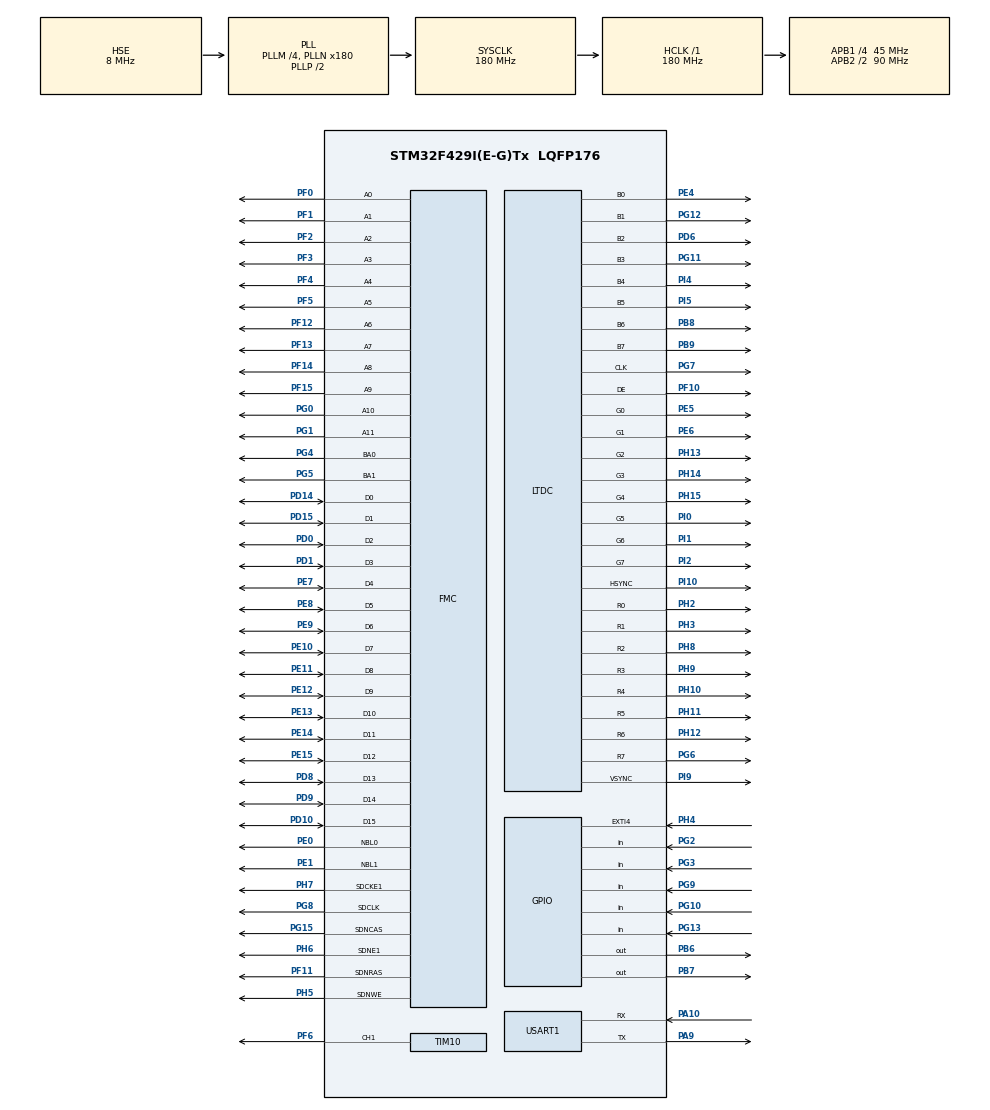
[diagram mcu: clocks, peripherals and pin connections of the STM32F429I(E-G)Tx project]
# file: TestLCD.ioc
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DMA2D.BytesSwap=DMA2D_BYTES_REGULAR
DMA2D.ColorMode=DMA2D_OUTPUT_RGB565
DMA2D.Mode=DMA2D_M2M
FMC.CASLatency1=FMC_SDRAM_CAS_LATENCY_3
FMC.ExitSelfRefreshDelay1=7
FMC.LoadToActiveDelay1=2
FMC.RCDDelay1=2
FMC.RPDelay1=2
FMC.RPDelay2=2
FMC.ReadBurst1=FMC_SDRAM_RBURST_ENABLE
FMC.ReadBurst2=FMC_SDRAM_RBURST_ENABLE
FMC.ReadPipeDelay1=FMC_SDRAM_RPIPE_DELAY_1
FMC.ReadPipeDelay2=FMC_SDRAM_RPIPE_DELAY_1
FMC.RowCycleDelay1=6
FMC.RowCycleDelay2=6
FMC.SDClockPeriod1=FMC_SDRAM_CLOCK_PERIOD_2
FMC.SDClockPeriod2=FMC_SDRAM_CLOCK_PERIOD_2
FMC.SelfRefreshTime1=4
FMC.WriteRecoveryTime1=2
FREERTOS.Tasks01=defaultTask,0,4096,StartDefaultTask,Default,NULL,Dynamic,NULL,NULL
FREERTOS.configTOTAL_HEAP_SIZE=30000
LTDC.ActiveW=800
LTDC.Alpha_L0=255
LTDC.FBStartAdress_L0=0xD0000000
LTDC.HBP=13
LTDC.HFP=32
LTDC.HSync=41
LTDC.ImageHeight_L0=480
LTDC.ImageWidth_L0=800
LTDC.Layers=0
LTDC.PixelFormat_L0=LTDC_PIXEL_FORMAT_RGB565
LTDC.VSync=10
LTDC.WindowX1_L0=800
LTDC.WindowY1_L0=480
Mcu.Family=STM32F4
Mcu.Name=STM32F429I(E-G)Tx
Mcu.Package=LQFP176
NVIC.DMA2D_IRQn=true\:5\:0\:false\:false\:true\:true\:true\:true
NVIC.EXTI4_IRQn=true\:0\:0\:false\:false\:true\:false\:true\:true
NVIC.LTDC_IRQn=true\:5\:0\:false\:false\:true\:true\:true\:true
NVIC.PriorityGroup=NVIC_PRIORITYGROUP_4
NVIC.TIM6_DAC_IRQn=true\:0\:0\:false\:false\:true\:false\:false\:true
NVIC.TimeBase=TIM6_DAC_IRQn
NVIC.TimeBaseIP=TIM6
PA10.Mode=Asynchronous
PA10.Signal=USART1_RX
PA13.Mode=Serial_Wire
PA13.Signal=SYS_JTMS-SWDIO
PA14.Mode=Serial_Wire
PA14.Signal=SYS_JTCK-SWCLK
PA9.Mode=Asynchronous
PA9.Signal=USART1_TX
PB6.GPIO_Speed=GPIO_SPEED_FREQ_VERY_HIGH
PB6.Signal=GPIO_Output
PB7.GPIO_Speed=GPIO_SPEED_FREQ_VERY_HIGH
PB7.Signal=GPIO_Output
PB8.GPIO_Speed=GPIO_SPEED_FREQ_VERY_HIGH
PB8.Mode=RGB888
PB8.Signal=LTDC_B6
PB9.GPIO_Speed=GPIO_SPEED_FREQ_VERY_HIGH
PB9.Mode=RGB888
PB9.Signal=LTDC_B7
PD0.Signal=FMC_D2_DA2
PD1.Signal=FMC_D3_DA3
PD10.Signal=FMC_D15_DA15
PD14.Signal=FMC_D0_DA0
PD15.Signal=FMC_D1_DA1
PD6.GPIO_Speed=GPIO_SPEED_FREQ_VERY_HIGH
PD6.Mode=RGB888
PD6.Signal=LTDC_B2
PD8.Signal=FMC_D13_DA13
PD9.Signal=FMC_D14_DA14
PE0.Signal=FMC_NBL0
PE1.Signal=FMC_NBL1
PE10.Signal=FMC_D7_DA7
PE11.Signal=FMC_D8_DA8
PE12.Signal=FMC_D9_DA9
PE13.Signal=FMC_D10_DA10
PE14.Signal=FMC_D11_DA11
PE15.Signal=FMC_D12_DA12
PE4.GPIO_Speed=GPIO_SPEED_FREQ_VERY_HIGH
PE4.Mode=RGB888
PE4.Signal=LTDC_B0
PE5.GPIO_Speed=GPIO_SPEED_FREQ_VERY_HIGH
PE5.Mode=RGB888
PE5.Signal=LTDC_G0
PE6.GPIO_Speed=GPIO_SPEED_FREQ_VERY_HIGH
PE6.Mode=RGB888
PE6.Signal=LTDC_G1
PE7.Signal=FMC_D4_DA4
PE8.Signal=FMC_D5_DA5
PE9.Signal=FMC_D6_DA6
PF0.Signal=FMC_A0
PF1.Signal=FMC_A1
PF10.GPIO_Speed=GPIO_SPEED_FREQ_VERY_HIGH
PF10.Mode=RGB888
PF10.Signal=LTDC_DE
PF11.Signal=FMC_SDNRAS
PF12.Signal=FMC_A6
PF13.Signal=FMC_A7
PF14.Signal=FMC_A8
PF15.Signal=FMC_A9
PF2.Signal=FMC_A2
PF3.Signal=FMC_A3
PF4.Signal=FMC_A4
PF5.Signal=FMC_A5
PF6.Signal=S_TIM10_CH1
PG0.Signal=FMC_A10
PG1.Signal=FMC_A11
PG10.Signal=GPIO_Input
PG11.GPIO_Speed=GPIO_SPEED_FREQ_VERY_HIGH
PG11.Mode=RGB888
PG11.Signal=LTDC_B3
PG12.GPIO_Speed=GPIO_SPEED_FREQ_VERY_HIGH
PG12.Mode=RGB888
PG12.Signal=LTDC_B1
PG13.Signal=GPIO_Input
PG15.Signal=FMC_SDNCAS
PG2.Signal=GPIO_Input
PG3.Signal=GPIO_Input
PG4.Signal=FMC_A14_BA0
PG5.Signal=FMC_A15_BA1
PG6.GPIO_Speed=GPIO_SPEED_FREQ_VERY_HIGH
PG6.Mode=RGB888
PG6.Signal=LTDC_R7
PG7.GPIO_Speed=GPIO_SPEED_FREQ_VERY_HIGH
PG7.Mode=RGB888
PG7.Signal=LTDC_CLK
PG8.Signal=FMC_SDCLK
PG9.Signal=GPIO_Input
PH0/OSC_IN.Mode=HSE-External-Oscillator
PH0/OSC_IN.Signal=RCC_OSC_IN
PH1/OSC_OUT.Mode=HSE-External-Oscillator
PH1/OSC_OUT.Signal=RCC_OSC_OUT
PH10.GPIO_Speed=GPIO_SPEED_FREQ_VERY_HIGH
PH10.Mode=RGB888
PH10.Signal=LTDC_R4
PH11.GPIO_Speed=GPIO_SPEED_FREQ_VERY_HIGH
PH11.Mode=RGB888
PH11.Signal=LTDC_R5
PH12.GPIO_Speed=GPIO_SPEED_FREQ_VERY_HIGH
PH12.Mode=RGB888
PH12.Signal=LTDC_R6
PH13.GPIO_Speed=GPIO_SPEED_FREQ_VERY_HIGH
PH13.Mode=RGB888
PH13.Signal=LTDC_G2
PH14.GPIO_Speed=GPIO_SPEED_FREQ_VERY_HIGH
PH14.Mode=RGB888
PH14.Signal=LTDC_G3
PH15.GPIO_Speed=GPIO_SPEED_FREQ_VERY_HIGH
PH15.Mode=RGB888
PH15.Signal=LTDC_G4
PH2.GPIO_Speed=GPIO_SPEED_FREQ_VERY_HIGH
PH2.Mode=RGB888
PH2.Signal=LTDC_R0
PH3.GPIO_Speed=GPIO_SPEED_FREQ_VERY_HIGH
PH3.Mode=RGB888
PH3.Signal=LTDC_R1
PH4.Signal=GPXTI4
PH5.Signal=FMC_SDNWE
PH6.Mode=SdramChipSelect2_1
PH6.Signal=FMC_SDNE1
PH7.Mode=SdramChipSelect2_1
PH7.Signal=FMC_SDCKE1
PH8.GPIO_Speed=GPIO_SPEED_FREQ_VERY_HIGH
PH8.Mode=RGB888
PH8.Signal=LTDC_R2
PH9.GPIO_Speed=GPIO_SPEED_FREQ_VERY_HIGH
PH9.Mode=RGB888
PH9.Signal=LTDC_R3
PI0.GPIO_Speed=GPIO_SPEED_FREQ_VERY_HIGH
PI0.Mode=RGB888
PI0.Signal=LTDC_G5
PI1.GPIO_Speed=GPIO_SPEED_FREQ_VERY_HIGH
PI1.Mode=RGB888
PI1.Signal=LTDC_G6
PI10.GPIO_Speed=GPIO_SPEED_FREQ_VERY_HIGH
PI10.Mode=RGB888
PI10.Signal=LTDC_HSYNC
PI2.GPIO_Speed=GPIO_SPEED_FREQ_VERY_HIGH
PI2.Mode=RGB888
PI2.Signal=LTDC_G7
PI4.GPIO_Speed=GPIO_SPEED_FREQ_VERY_HIGH
PI4.Mode=RGB888
PI4.Signal=LTDC_B4
PI5.GPIO_Speed=GPIO_SPEED_FREQ_VERY_HIGH
PI5.Mode=RGB888
PI5.Signal=LTDC_B5
PI9.GPIO_Speed=GPIO_SPEED_FREQ_VERY_HIGH
PI9.Mode=RGB888
PI9.Signal=LTDC_VSYNC
ProjectManager.HeapSize=0x200
ProjectManager.StackSize=0x400
ProjectManager.TargetToolchain=TrueSTUDIO
RCC.48MHZClocksFreq_Value=90000000
RCC.AHBFreq_Value=180000000
RCC.APB1CLKDivider=RCC_HCLK_DIV4
RCC.APB1Freq_Value=45000000
RCC.APB1TimFreq_Value=90000000
RCC.APB2CLKDivider=RCC_HCLK_DIV2
RCC.APB2Freq_Value=90000000
RCC.APB2TimFreq_Value=180000000
RCC.CortexFreq_Value=180000000
RCC.HCLKFreq_Value=180000000
RCC.HSE_VALUE=8000000
RCC.HSI_VALUE=16000000
RCC.LSE_VALUE=32768
RCC.PLLM=4
RCC.PLLN=180
RCC.PLLSAIN=50
RCC.PLLSourceVirtual=RCC_PLLSOURCE_HSE
RCC.SYSCLKFreq_VALUE=180000000
RCC.SYSCLKSource=RCC_SYSCLKSOURCE_PLLCLK
RCC.VCOOutputFreq_Value=360000000
SH.FMC_A0.0=FMC_A0,12b-sda1
SH.FMC_A1.0=FMC_A1,12b-sda1
SH.FMC_A10.0=FMC_A10,12b-sda1
SH.FMC_A11.0=FMC_A11,12b-sda1
SH.FMC_A14_BA0.0=FMC_BA0,FourSdramBanks1
SH.FMC_A15_BA1.0=FMC_BA1,FourSdramBanks1
SH.FMC_A2.0=FMC_A2,12b-sda1
SH.FMC_A3.0=FMC_A3,12b-sda1
SH.FMC_A4.0=FMC_A4,12b-sda1
SH.FMC_A5.0=FMC_A5,12b-sda1
SH.FMC_A6.0=FMC_A6,12b-sda1
SH.FMC_A7.0=FMC_A7,12b-sda1
SH.FMC_A8.0=FMC_A8,12b-sda1
SH.FMC_A9.0=FMC_A9,12b-sda1
SH.FMC_D0_DA0.0=FMC_D0,sd-16b-d1
SH.FMC_D10_DA10.0=FMC_D10,sd-16b-d1
SH.FMC_D11_DA11.0=FMC_D11,sd-16b-d1
SH.FMC_D12_DA12.0=FMC_D12,sd-16b-d1
SH.FMC_D13_DA13.0=FMC_D13,sd-16b-d1
SH.FMC_D14_DA14.0=FMC_D14,sd-16b-d1
SH.FMC_D15_DA15.0=FMC_D15,sd-16b-d1
SH.FMC_D1_DA1.0=FMC_D1,sd-16b-d1
SH.FMC_D2_DA2.0=FMC_D2,sd-16b-d1
SH.FMC_D3_DA3.0=FMC_D3,sd-16b-d1
SH.FMC_D4_DA4.0=FMC_D4,sd-16b-d1
SH.FMC_D5_DA5.0=FMC_D5,sd-16b-d1
SH.FMC_D6_DA6.0=FMC_D6,sd-16b-d1
SH.FMC_D7_DA7.0=FMC_D7,sd-16b-d1
SH.FMC_D8_DA8.0=FMC_D8,sd-16b-d1
SH.FMC_D9_DA9.0=FMC_D9,sd-16b-d1
SH.FMC_NBL0.0=FMC_NBL0,Sd2ByteEnable1
SH.FMC_NBL1.0=FMC_NBL1,Sd2ByteEnable1
SH.FMC_SDCLK.0=FMC_SDCLK,12b-sda1
SH.FMC_SDNCAS.0=FMC_SDNCAS,12b-sda1
SH.FMC_SDNRAS.0=FMC_SDNRAS,12b-sda1
SH.FMC_SDNWE.0=FMC_SDNWE,12b-sda1
SH.S_TIM10_CH1.0=TIM10_CH1,PWM Generation1 CH1
STMicroelectronics.X-CUBE-TOUCHGFX.4.13.0.ApplicationCcGraphicsJjApplication=TouchGFXOoGenerator
STMicroelectronics.X-CUBE-TOUCHGFX.4.13.0.tgfx_address1=0xD0000000
STMicroelectronics.X-CUBE-TOUCHGFX.4.13.0.tgfx_display_interface=disp_ltdc
STMicroelectronics.X-CUBE-TOUCHGFX.4.13.0.tgfx_hardware_accelerator=dma_2d
STMicroelectronics.X-CUBE-TOUCHGFX.4.13.0.tgfx_location=By Address
STMicroelectronics.X-CUBE-TOUCHGFX.4.13.0.tgfx_vsync=vsync_ltdc
TIM10.Channel=TIM_CHANNEL_1
TIM10.Period=10000
TIM10.Prescaler=180
USART1.VirtualMode=VM_ASYNC
VP_CRC_VS_CRC.Mode=CRC_Activate
VP_DMA2D_VS_DMA2D.Mode=DMA2D_Activate
VP_FREERTOS_VS_CMSIS_V1.Mode=CMSIS_V1
VP_STMicroelectronics.X-CUBE-TOUCHGFX_VS_GraphicsJjApplication_4.13.0.Mode=GraphicsJjApplication
VP_SYS_VS_tim6.Mode=TIM6
VP_TIM10_VS_ClockSourceINT.Mode=Enable_Timer
board=custom

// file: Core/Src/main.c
/* USER CODE BEGIN Header */
/**
  ******************************************************************************
  * @file           : main.c
  * @brief          : Main program body
  ******************************************************************************
  * @attention
  *
  * <h2><center>&copy; Copyright (c) 2020 STMicroelectronics.
  * All rights reserved.</center></h2>
  *
  * This software component is licensed by ST under BSD 3-Clause license,
  * the "License"; You may not use this file except in compliance with the
  * License. You may obtain a copy of the License at:
  *                        opensource.org/licenses/BSD-3-Clause
  *
  ******************************************************************************
  */
/* USER CODE END Header */

#include "main.h"
#include "cmsis_os.h"
#include "app_touchgfx.h"

/* USER CODE BEGIN Includes */
#include "GT911.h"
#include "sdram_IS42S16400J.h"
#include "mainOS.h"

/* USER CODE END Includes */

CRC_HandleTypeDef hcrc;

DMA2D_HandleTypeDef hdma2d;

LTDC_HandleTypeDef hltdc;

TIM_HandleTypeDef htim10;

UART_HandleTypeDef huart1;

SDRAM_HandleTypeDef hsdram1;

osThreadId defaultTaskHandle;

void SystemClock_Config(void);
static void MX_GPIO_Init(void);
static void MX_LTDC_Init(void);
static void MX_FMC_Init(void);
static void MX_CRC_Init(void);
static void MX_TIM10_Init(void);
static void MX_DMA2D_Init(void);
static void MX_USART1_UART_Init(void);
void StartDefaultTask(void const * argument);

int main(void)
{

  /* MCU Configuration--------------------------------------------------------*/

  /* Reset of all peripherals, Initializes the Flash interface and the Systick. */
  HAL_Init();

  /* Configure the system clock */
  SystemClock_Config();

  /* USER CODE BEGIN SysInit */
  GT911_Reset_Sequence();
  /* USER CODE END SysInit */

  /* Initialize all configured peripherals */
  MX_GPIO_Init();
  MX_LTDC_Init();
  MX_FMC_Init();
  MX_CRC_Init();
  MX_TIM10_Init();
  MX_DMA2D_Init();
  MX_USART1_UART_Init();
  MX_TouchGFX_Init();
  /* USER CODE BEGIN 2 */
  SDRAM_IS42S16400J_Initialization(&hsdram1);

  /* USER CODE END 2 */

  /* Create the thread(s) */
  /* definition and creation of defaultTask */
  osThreadDef(defaultTask, StartDefaultTask, osPriorityNormal, 0, 4096);
  defaultTaskHandle = osThreadCreate(osThread(defaultTask), NULL);

  /* USER CODE BEGIN RTOS_THREADS */
  /* add threads, ... */
  createAllTask();
  /* USER CODE END RTOS_THREADS */

  /* Start scheduler */
  osKernelStart();

  /* We should never get here as control is now taken by the scheduler */
  /* Infinite loop */
  while (1)
  {

  }
}

void SystemClock_Config(void)
{
  RCC_OscInitTypeDef RCC_OscInitStruct = {0};
  RCC_ClkInitTypeDef RCC_ClkInitStruct = {0};
  RCC_PeriphCLKInitTypeDef PeriphClkInitStruct = {0};

  /** Configure the main internal regulator output voltage
  */
  __HAL_RCC_PWR_CLK_ENABLE();
  __HAL_PWR_VOLTAGESCALING_CONFIG(PWR_REGULATOR_VOLTAGE_SCALE1);
  /** Initializes the CPU, AHB and APB busses clocks
  */
  RCC_OscInitStruct.OscillatorType = RCC_OSCILLATORTYPE_HSE;
  RCC_OscInitStruct.HSEState = RCC_HSE_ON;
  RCC_OscInitStruct.PLL.PLLState = RCC_PLL_ON;
  RCC_OscInitStruct.PLL.PLLSource = RCC_PLLSOURCE_HSE;
  RCC_OscInitStruct.PLL.PLLM = 4;
  RCC_OscInitStruct.PLL.PLLN = 180;
  RCC_OscInitStruct.PLL.PLLP = RCC_PLLP_DIV2;
  RCC_OscInitStruct.PLL.PLLQ = 4;
  if (HAL_RCC_OscConfig(&RCC_OscInitStruct) != HAL_OK)
  {
    Error_Handler();
  }
  /** Activate the Over-Drive mode
  */
  if (HAL_PWREx_EnableOverDrive() != HAL_OK)
  {
    Error_Handler();
  }
  /** Initializes the CPU, AHB and APB busses clocks
  */
  RCC_ClkInitStruct.ClockType = RCC_CLOCKTYPE_HCLK|RCC_CLOCKTYPE_SYSCLK
                              |RCC_CLOCKTYPE_PCLK1|RCC_CLOCKTYPE_PCLK2;
  RCC_ClkInitStruct.SYSCLKSource = RCC_SYSCLKSOURCE_PLLCLK;
  RCC_ClkInitStruct.AHBCLKDivider = RCC_SYSCLK_DIV1;
  RCC_ClkInitStruct.APB1CLKDivider = RCC_HCLK_DIV4;
  RCC_ClkInitStruct.APB2CLKDivider = RCC_HCLK_DIV2;

  if (HAL_RCC_ClockConfig(&RCC_ClkInitStruct, FLASH_LATENCY_5) != HAL_OK)
  {
    Error_Handler();
  }
  PeriphClkInitStruct.PeriphClockSelection = RCC_PERIPHCLK_LTDC;
  PeriphClkInitStruct.PLLSAI.PLLSAIN = 50;
  PeriphClkInitStruct.PLLSAI.PLLSAIR = 2;
  PeriphClkInitStruct.PLLSAIDivR = RCC_PLLSAIDIVR_2;
  if (HAL_RCCEx_PeriphCLKConfig(&PeriphClkInitStruct) != HAL_OK)
  {
    Error_Handler();
  }
}

static void MX_CRC_Init(void)
{

  hcrc.Instance = CRC;
  if (HAL_CRC_Init(&hcrc) != HAL_OK)
  {
    Error_Handler();
  }

}

static void MX_DMA2D_Init(void)
{

  hdma2d.Instance = DMA2D;
  hdma2d.Init.Mode = DMA2D_M2M;
  hdma2d.Init.ColorMode = DMA2D_OUTPUT_RGB565;
  hdma2d.Init.OutputOffset = 0;
  hdma2d.LayerCfg[1].InputOffset = 0;
  hdma2d.LayerCfg[1].InputColorMode = DMA2D_INPUT_RGB565;
  hdma2d.LayerCfg[1].AlphaMode = DMA2D_NO_MODIF_ALPHA;
  hdma2d.LayerCfg[1].InputAlpha = 0;
  if (HAL_DMA2D_Init(&hdma2d) != HAL_OK)
  {
    Error_Handler();
  }
  if (HAL_DMA2D_ConfigLayer(&hdma2d, 1) != HAL_OK)
  {
    Error_Handler();
  }

}

static void MX_LTDC_Init(void)
{

  LTDC_LayerCfgTypeDef pLayerCfg = {0};

  hltdc.Instance = LTDC;
  hltdc.Init.HSPolarity = LTDC_HSPOLARITY_AL;
  hltdc.Init.VSPolarity = LTDC_VSPOLARITY_AL;
  hltdc.Init.DEPolarity = LTDC_DEPOLARITY_AL;
  hltdc.Init.PCPolarity = LTDC_PCPOLARITY_IPC;
  hltdc.Init.HorizontalSync = 40;
  hltdc.Init.VerticalSync = 9;
  hltdc.Init.AccumulatedHBP = 53;
  hltdc.Init.AccumulatedVBP = 11;
  hltdc.Init.AccumulatedActiveW = 853;
  hltdc.Init.AccumulatedActiveH = 491;
  hltdc.Init.TotalWidth = 885;
  hltdc.Init.TotalHeigh = 493;
  hltdc.Init.Backcolor.Blue = 0;
  hltdc.Init.Backcolor.Green = 0;
  hltdc.Init.Backcolor.Red = 0;
  if (HAL_LTDC_Init(&hltdc) != HAL_OK)
  {
    Error_Handler();
  }
  pLayerCfg.WindowX0 = 0;
  pLayerCfg.WindowX1 = 800;
  pLayerCfg.WindowY0 = 0;
  pLayerCfg.WindowY1 = 480;
  pLayerCfg.PixelFormat = LTDC_PIXEL_FORMAT_RGB565;
  pLayerCfg.Alpha = 255;
  pLayerCfg.Alpha0 = 0;
  pLayerCfg.BlendingFactor1 = LTDC_BLENDING_FACTOR1_CA;
  pLayerCfg.BlendingFactor2 = LTDC_BLENDING_FACTOR2_CA;
  pLayerCfg.FBStartAdress = 0xD0000000;
  pLayerCfg.ImageWidth = 800;
  pLayerCfg.ImageHeight = 480;
  pLayerCfg.Backcolor.Blue = 0;
  pLayerCfg.Backcolor.Green = 0;
  pLayerCfg.Backcolor.Red = 0;
  if (HAL_LTDC_ConfigLayer(&hltdc, &pLayerCfg, 0) != HAL_OK)
  {
    Error_Handler();
  }

}

static void MX_TIM10_Init(void)
{

  TIM_OC_InitTypeDef sConfigOC = {0};

  htim10.Instance = TIM10;
  htim10.Init.Prescaler = 180;
  htim10.Init.CounterMode = TIM_COUNTERMODE_UP;
  htim10.Init.Period = 10000;
  htim10.Init.ClockDivision = TIM_CLOCKDIVISION_DIV1;
  htim10.Init.AutoReloadPreload = TIM_AUTORELOAD_PRELOAD_DISABLE;
  if (HAL_TIM_Base_Init(&htim10) != HAL_OK)
  {
    Error_Handler();
  }
  if (HAL_TIM_PWM_Init(&htim10) != HAL_OK)
  {
    Error_Handler();
  }
  sConfigOC.OCMode = TIM_OCMODE_PWM1;
  sConfigOC.Pulse = 0;
  sConfigOC.OCPolarity = TIM_OCPOLARITY_HIGH;
  sConfigOC.OCFastMode = TIM_OCFAST_DISABLE;
  if (HAL_TIM_PWM_ConfigChannel(&htim10, &sConfigOC, TIM_CHANNEL_1) != HAL_OK)
  {
    Error_Handler();
  }
  HAL_TIM_MspPostInit(&htim10);

}

static void MX_USART1_UART_Init(void)
{

  huart1.Instance = USART1;
  huart1.Init.BaudRate = 115200;
  huart1.Init.WordLength = UART_WORDLENGTH_8B;
  huart1.Init.StopBits = UART_STOPBITS_1;
  huart1.Init.Parity = UART_PARITY_NONE;
  huart1.Init.Mode = UART_MODE_TX_RX;
  huart1.Init.HwFlowCtl = UART_HWCONTROL_NONE;
  huart1.Init.OverSampling = UART_OVERSAMPLING_16;
  if (HAL_UART_Init(&huart1) != HAL_OK)
  {
    Error_Handler();
  }

}

/* FMC initialization function */
static void MX_FMC_Init(void)
{

  FMC_SDRAM_TimingTypeDef SdramTiming = {0};

  /** Perform the SDRAM1 memory initialization sequence
  */
  hsdram1.Instance = FMC_SDRAM_DEVICE;
  /* hsdram1.Init */
  hsdram1.Init.SDBank = FMC_SDRAM_BANK2;
  hsdram1.Init.ColumnBitsNumber = FMC_SDRAM_COLUMN_BITS_NUM_8;
  hsdram1.Init.RowBitsNumber = FMC_SDRAM_ROW_BITS_NUM_12;
  hsdram1.Init.MemoryDataWidth = FMC_SDRAM_MEM_BUS_WIDTH_16;
  hsdram1.Init.InternalBankNumber = FMC_SDRAM_INTERN_BANKS_NUM_4;
  hsdram1.Init.CASLatency = FMC_SDRAM_CAS_LATENCY_3;
  hsdram1.Init.WriteProtection = FMC_SDRAM_WRITE_PROTECTION_DISABLE;
  hsdram1.Init.SDClockPeriod = FMC_SDRAM_CLOCK_PERIOD_2;
  hsdram1.Init.ReadBurst = FMC_SDRAM_RBURST_ENABLE;
  hsdram1.Init.ReadPipeDelay = FMC_SDRAM_RPIPE_DELAY_1;
  /* SdramTiming */
  SdramTiming.LoadToActiveDelay = 2;
  SdramTiming.ExitSelfRefreshDelay = 7;
  SdramTiming.SelfRefreshTime = 4;
  SdramTiming.RowCycleDelay = 6;
  SdramTiming.WriteRecoveryTime = 2;
  SdramTiming.RPDelay = 2;
  SdramTiming.RCDDelay = 2;

  if (HAL_SDRAM_Init(&hsdram1, &SdramTiming) != HAL_OK)
  {
    Error_Handler( );
  }

}

static void MX_GPIO_Init(void)
{
  GPIO_InitTypeDef GPIO_InitStruct = {0};

  /* GPIO Ports Clock Enable */
  __HAL_RCC_GPIOE_CLK_ENABLE();
  __HAL_RCC_GPIOI_CLK_ENABLE();
  __HAL_RCC_GPIOF_CLK_ENABLE();
  __HAL_RCC_GPIOH_CLK_ENABLE();
  __HAL_RCC_GPIOG_CLK_ENABLE();
  __HAL_RCC_GPIOD_CLK_ENABLE();
  __HAL_RCC_GPIOA_CLK_ENABLE();
  __HAL_RCC_GPIOB_CLK_ENABLE();

  /*Configure GPIO pin Output Level */
  HAL_GPIO_WritePin(GPIOB, GPIO_PIN_6|GPIO_PIN_7, GPIO_PIN_RESET);

  /*Configure GPIO pin : PH4 */
  GPIO_InitStruct.Pin = GPIO_PIN_4;
  GPIO_InitStruct.Mode = GPIO_MODE_IT_RISING;
  GPIO_InitStruct.Pull = GPIO_NOPULL;
  HAL_GPIO_Init(GPIOH, &GPIO_InitStruct);

  /*Configure GPIO pins : PG2 PG3 PG9 PG10
                           PG13 */
  GPIO_InitStruct.Pin = GPIO_PIN_2|GPIO_PIN_3|GPIO_PIN_9|GPIO_PIN_10
                          |GPIO_PIN_13;
  GPIO_InitStruct.Mode = GPIO_MODE_INPUT;
  GPIO_InitStruct.Pull = GPIO_NOPULL;
  HAL_GPIO_Init(GPIOG, &GPIO_InitStruct);

  /*Configure GPIO pins : PB6 PB7 */
  GPIO_InitStruct.Pin = GPIO_PIN_6|GPIO_PIN_7;
  GPIO_InitStruct.Mode = GPIO_MODE_OUTPUT_PP;
  GPIO_InitStruct.Pull = GPIO_NOPULL;
  GPIO_InitStruct.Speed = GPIO_SPEED_FREQ_VERY_HIGH;
  HAL_GPIO_Init(GPIOB, &GPIO_InitStruct);

  /* EXTI interrupt init*/
  HAL_NVIC_SetPriority(EXTI4_IRQn, 0, 0);
  HAL_NVIC_EnableIRQ(EXTI4_IRQn);

}

void StartDefaultTask(void const * argument)
{
  /* USER CODE BEGIN 5 */
  /* Infinite loop */

	MX_TouchGFX_Process();
  for(;;)
  {
    osDelay(1);
  }
  /* USER CODE END 5 */
}

 /**
  * @brief  Period elapsed callback in non blocking mode
  * @note   This function is called  when TIM6 interrupt took place, inside
  * HAL_TIM_IRQHandler(). It makes a direct call to HAL_IncTick() to increment
  * a global variable "uwTick" used as application time base.
  * @param  htim : TIM handle
  * @retval None
  */
void HAL_TIM_PeriodElapsedCallback(TIM_HandleTypeDef *htim)
{
  if (htim->Instance == TIM6) {
    HAL_IncTick();
  }
}

void Error_Handler(void)
{
}

/************************ (C) COPYRIGHT STMicroelectronics *****END OF FILE****/
